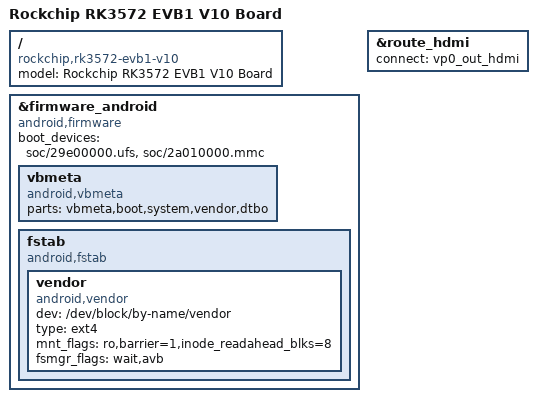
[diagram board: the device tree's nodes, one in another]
// SPDX-License-Identifier: (GPL-2.0+ OR MIT)
/*
 * Copyright (c) 2026 Rockchip Electronics Co., Ltd.
 *
 */

/dts-v1/;

#include "rk3572-evb1-v10.dtsi"
#include "rk3572-android9.dtsi"
#include "rk3572-evb1-cam-csi0.dtsi"

/ {
	model = "Rockchip RK3572 EVB1 V10 Board";
	compatible = "rockchip,rk3572-evb1-v10", "rockchip,rk3572", "rockchip,Android9";
};

&firmware_android {
	compatible = "android,firmware";
	boot_devices = "soc/29e00000.ufs, soc/2a010000.mmc";
	vbmeta {
		compatible = "android,vbmeta";
		parts = "vbmeta,boot,system,vendor,dtbo";
	};
	fstab {
		compatible = "android,fstab";
		vendor {
			compatible = "android,vendor";
			dev = "/dev/block/by-name/vendor";
			type = "ext4";
			mnt_flags = "ro,barrier=1,inode_readahead_blks=8";
			fsmgr_flags = "wait,avb";
		};
	};
};

&route_hdmi {
	status = "okay";
	connect = <&vp0_out_hdmi>;
};
